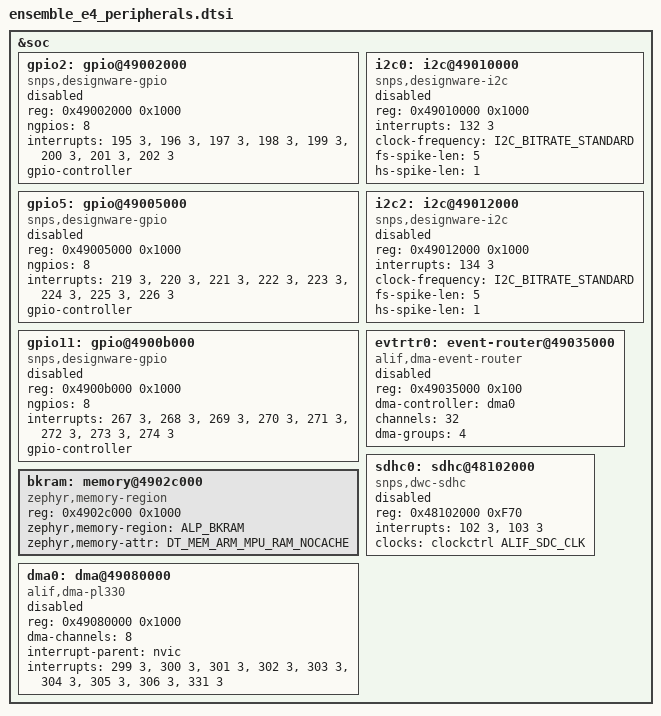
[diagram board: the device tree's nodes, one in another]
/*
 * Copyright (c) 2026 Alp Lab AB
 * SPDX-License-Identifier: Apache-2.0
 *
 * alp-sdk peripheral nodes for the Alif Ensemble E4 (AE402FA0E5597) M55-HP
 * board (E1M-AEN401) that upstream Zephyr's Alif SoC layer does not declare:
 *
 *   gpio2    -- CC3501E bridge READY line (P2_6)
 *   i2c2     -- E1M I2C0 / EEPROM identity bus (0x50, 0x58)
 *   dma0 + evtrtr0 -- PL330 system DMA and its event router (SPI1 DMA)
 *   sdhc0    -- SD/MMC host (microSD in the EVK J7 slot)
 *
 * The node bodies are copied VERBATIM from ensemble_e8_peripherals.dtsi.
 * They hold on the E4 because the Alif DFP for THIS part,
 * Device/soc/AE402FA0E5597/include/rtss_hp/soc.h, gives the same values:
 * SDMMC_BASE 0x48102000 (:3571), SDMMC_IRQ_IRQn 102 and
 * SDMMC_WAKEUP_IRQ_IRQn 103 (:182-183), GPIO2_BASE 0x49002000 (:3581),
 * GPIO2_IRQ0..7_IRQn 195..202 (:276-283), I2C2_BASE 0x49012000 (:3596),
 * I2C2_IRQ_IRQn 134 (:214), EVTRTR0_BASE 0x49035000 (:3645),
 * DMA0_SEC_BASE 0x49080000 (:3652), DMA0_IRQ0..7_IRQn 299..306 (:380-394),
 * DMA0_IRQ_ABORT_IRQn 331 (:444).
 *
 * Every node stays status = "disabled"; a board overlay or shield enables
 * what its carrier wires (e.g. the e1m_evk_microsd shield for sdhc0).
 * gpio2, i2c2 and sdhc0 were bench-verified on an E1M-AEN401 M55-HP on
 * 2026-10-12 (bridge READY, EEPROM read/write, 4-bit SD at 25 MHz) from an
 * app overlay with these exact values; dma0/evtrtr0 are not yet verified on
 * the E4.
 */

#include <zephyr/dt-bindings/clock/alif-ensemble-clocks-ext.h>
#include <zephyr/dt-bindings/i2c/i2c.h>
#include <zephyr/dt-bindings/memory-attr/memory-attr-arm.h>

&soc {
	gpio2: gpio@49002000 {
		compatible = "snps,designware-gpio";
		reg = <0x49002000 0x1000>;
		ngpios = <8>;
		interrupts = <195 3>, <196 3>, <197 3>, <198 3>,
			     <199 3>, <200 3>, <201 3>, <202 3>;
		gpio-controller;
		#gpio-cells = <2>;
		status = "disabled";
	};

	/* GPIO5 / GPIO11 / I2C0: AE402FA0E5597 soc.h GPIO5_BASE 0x49005000
	 * (GPIO5_IRQ0..7 = 219..226), GPIO11_BASE 0x4900B000 (GPIO11_IRQ0..7 =
	 * 267..274), I2C0_BASE 0x49010000 (I2C0_IRQ = 132) -- the same values as
	 * the E8 nodes.  Used by the AEN401 SoM power layer (backlight enable P5_5,
	 * PHY reset P11_6) and the on-module BRD_I2C bus.  Not yet bench-run on E4.
	 */
	gpio5: gpio@49005000 {
		compatible = "snps,designware-gpio";
		reg = <0x49005000 0x1000>;
		ngpios = <8>;
		interrupts = <219 3>, <220 3>, <221 3>, <222 3>,
			     <223 3>, <224 3>, <225 3>, <226 3>;
		gpio-controller;
		#gpio-cells = <2>;
		status = "disabled";
	};

	gpio11: gpio@4900b000 {
		compatible = "snps,designware-gpio";
		reg = <0x4900b000 0x1000>;
		ngpios = <8>;
		interrupts = <267 3>, <268 3>, <269 3>, <270 3>,
			     <271 3>, <272 3>, <273 3>, <274 3>;
		gpio-controller;
		#gpio-cells = <2>;
		status = "disabled";
	};

	i2c0: i2c@49010000 {
		compatible = "snps,designware-i2c";
		#address-cells = <1>;
		#size-cells = <0>;
		reg = <0x49010000 0x1000>;
		interrupts = <132 3>;
		clock-frequency = <I2C_BITRATE_STANDARD>;
		fs-spike-len = <5>;
		hs-spike-len = <1>;
		status = "disabled";
	};

	/* The 4 KB Utility (backup) SRAM that carries the STOP wake record
	 * (src/backends/power/som_power_record.c).  INFERRED for the E4, not read
	 * from an E4 source: the DFP ships no E4 SVD, and the E4 soc.h names no
	 * BKRAM.  0x4902C000 / 4 KB is the <memory name="Backup_SRAM"> of the
	 * AE302 (E3) and AE722 (E7) SVDs and the E8 address bench-proven to survive
	 * STOP (ensemble_e8_peripherals.dtsi).  Survival across STOP on the E4 is
	 * unverified.
	 */
	bkram: memory@4902c000 {
		compatible = "zephyr,memory-region";
		reg = <0x4902c000 0x1000>;
		zephyr,memory-region = "ALP_BKRAM";
		/* Normal, non-cacheable RAM: a record write must reach the SRAM itself,
		 * never sit in a data cache across the STOP entry. */
		zephyr,memory-attr = <DT_MEM_ARM_MPU_RAM_NOCACHE>;
	};

	i2c2: i2c@49012000 {
		compatible = "snps,designware-i2c";
		#address-cells = <1>;
		#size-cells = <0>;
		reg = <0x49012000 0x1000>;
		interrupts = <134 3>;
		clock-frequency = <I2C_BITRATE_STANDARD>;
		fs-spike-len = <5>;
		hs-spike-len = <1>;
		status = "disabled";
	};

	dma0: dma@49080000 {
		compatible = "alif,dma-pl330";
		reg = <0x49080000 0x1000>;
		#dma-cells = <2>;
		dma-channels = <8>;
		interrupt-parent = <&nvic>;
		interrupts = <299 3>, <300 3>, <301 3>, <302 3>, <303 3>,
			     <304 3>, <305 3>, <306 3>, <331 3>;
		interrupt-names = "channel0", "channel1", "channel2", "channel3",
				  "channel4", "channel5", "channel6", "channel7", "abort";
		status = "disabled";
	};

	evtrtr0: event-router@49035000 {
		compatible = "alif,dma-event-router";
		reg = <0x49035000 0x100>;
		dma-controller = <&dma0>;
		channels = <32>;
		dma-groups = <4>;  /* SYSTOP router: 4 ACK_TYPE groups (0-3) */
		#dma-cells = <2>;
		status = "disabled";
	};

	sdhc0: sdhc@48102000 {
		compatible = "snps,dwc-sdhc";
		reg = <0x48102000 0xF70>;
		interrupts = <102 3>, <103 3>;
		interrupt-names = "sdmmc", "sdmmc_wakeup";
		clocks = <&clockctrl ALIF_SDC_CLK>;
		status = "disabled";
	};
};
